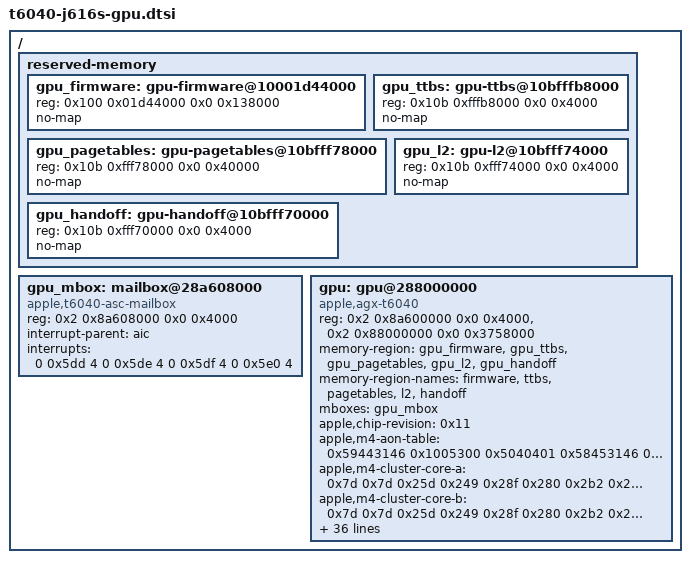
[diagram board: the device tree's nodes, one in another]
// SPDX-License-Identifier: GPL-2.0-only OR MIT
/*
 * Apple M4 Pro (T6040, j616s) GPU node and the memory iBoot reserves for the
 * GPU firmware. The node uses absolute physical addresses
 * (#address-cells = <2>, #size-cells = <2>).
 *
 * The apple,sgx-* properties are copies of the ADT /arm-io/sgx properties the
 * driver builds the firmware's hardware data and power configuration from;
 * the apple,m4-* properties hold this GPU's calibration tables (per-cluster
 * frequencies, voltages, core mask, leakage, AON table).
 */

/ {
	reserved-memory {
		#address-cells = <2>;
		#size-cells = <2>;
		ranges;

		/* __DATA segment of the GPU firmware (apple,sgx-gfx-data-*), holds its crash log */
		gpu_firmware: gpu-firmware@10001d44000 {
			reg = <0x100 0x01d44000 0x0 0x138000>;
			no-map;
		};
		/* apple,sgx-gpu-region-* */
		gpu_ttbs: gpu-ttbs@10bfffb8000 {
			reg = <0x10b 0xfffb8000 0x0 0x4000>;
			no-map;
		};
		/* apple,sgx-gfx-shared-region-* : UAT page tables */
		gpu_pagetables: gpu-pagetables@10bfff78000 {
			reg = <0x10b 0xfff78000 0x0 0x40000>;
			no-map;
		};
		/* apple,sgx-gfx-shared-l2-region-* */
		gpu_l2: gpu-l2@10bfff74000 {
			reg = <0x10b 0xfff74000 0x0 0x4000>;
			no-map;
		};
		/* apple,sgx-gfx-handoff-* */
		gpu_handoff: gpu-handoff@10bfff70000 {
			reg = <0x10b 0xfff70000 0x0 0x4000>;
			no-map;
		};
	};

	gpu_mbox: mailbox@28a608000 {
		compatible = "apple,t6040-asc-mailbox", "apple,asc-mailbox-v4";
		reg = <0x2 0x8a608000 0x0 0x4000>;
		interrupt-parent = <&aic>;
		interrupts = <0 0x5dd 4 0 0x5de 4 0 0x5df 4 0 0x5e0 4>;
		interrupt-names = "send-empty", "send-not-empty", "recv-empty", "recv-not-empty";
		#mbox-cells = <0>;
	};

	gpu: gpu@288000000 {
		compatible = "apple,agx-t6040";
		reg = <0x2 0x8a600000 0x0 0x4000>, <0x2 0x88000000 0x0 0x3758000>;
		reg-names = "asc", "sgx";
		memory-region = <&gpu_firmware>, <&gpu_ttbs>, <&gpu_pagetables>, <&gpu_l2>, <&gpu_handoff>;
		memory-region-names = "firmware", "ttbs", "pagetables", "l2", "handoff";
		mboxes = <&gpu_mbox>;

		apple,chip-revision = <0x11>;
		apple,m4-aon-table = <0x59443146 0x1005300 0x5040401 0x58453146 0x1008200 0xeff0000 0x57463146 0x1004600 0x1ff0000 0x43533146 0x1004700 0x9000800 0x4c533146 0x1005200 0x1030000 0x44543146 0x1005000 0x1010000 0x56543146 0x1005100 0x1020000 0x59443246 0x1009d00 0x5040401 0x58453246 0x100ca00 0xeff0000 0x57463246 0x1009000 0x1ff0000 0x43533246 0x1009100 0x9000800 0x4c533246 0x1009c00 0x1030000 0x44543246 0x1009a00 0x1010000 0x56543246 0x1009b00 0x1020000 0x5944314c 0x1000d00 0x5040401 0x5845314c 0x1003c00 0xaff0000 0x5746314c 0x1000000 0x1ff0000 0x4353314c 0x1000100 0x9000800 0x4c53314c 0x1000c00 0x1030000 0x4454314c 0x1000a00 0x1010000 0x5654314c 0x1000b00 0x1020000 0x31454d53 0x100da00 0x1ff0000 0x58454d53 0x100db00 0x2dff0000 0x45544d53 0x100d800 0x20a0100 0x53427462 0x1001b00 0x5090400 0x63447462 0x1001600 0x2070100 0x49467462 0x1001200 0x4050300 0x43577462 0x1001800 0x3070200 0x306d7462 0x1002000 0x1080000 0x316d7462 0x1002100 0x1080000 0x656e3064 0x1008100 0x1ff0000 0x696e3064 0x1003b00 0x1ff0000 0x526e3065 0x1003900 0x1ff0000 0x42453067 0x1006900 0x1ff0000 0x4c453067 0x1006700 0x1ff0000 0x42543067 0x1006a00 0x1ff0000 0x4c543067 0x1006800 0x1ff0000 0x52543067 0x1006b00 0x1140000 0x30653067 0x1006c00 0x2ff0000 0x31653067 0x1006e00 0x2ff0000 0x30693067 0x1007200 0x1ff0000 0x31693067 0x1007300 0x1ff0000 0x32693067 0x1007400 0x1ff0000 0x33693067 0x1007500 0x1ff0000 0x526e3067 0x1007e00 0x1ff0000 0x30743067 0x1007000 0x1ff0000 0x31743067 0x1007100 0x1ff0000 0x42453167 0x100b300 0x1ff0000 0x4c453167 0x100b100 0x1ff0000 0x42543167 0x100b400 0x1ff0000 0x4c543167 0x100b200 0x1ff0000 0x52543167 0x100b500 0x1140000 0x30653167 0x100b600 0x2ff0000 0x31653167 0x100b800 0x2ff0000 0x30693167 0x100bc00 0x1ff0000 0x31693167 0x100bd00 0x1ff0000 0x32693167 0x100be00 0x1ff0000 0x33693167 0x100bf00 0x1ff0000 0x526e3167 0x100c600 0x1ff0000 0x30743167 0x100ba00 0x1ff0000 0x31743167 0x100bb00 0x1ff0000 0x306e306c 0x1007f00 0x1ff0000 0x326e306c 0x1008000 0x1ff0000 0x306e316c 0x100c900 0x1ff0000 0x326e316c 0x1003a00 0x1ff0000 0x42453070 0x1005a00 0x1ff0000 0x4c453070 0x1005800 0x1ff0000 0x72453070 0x1007600 0x1ff0000 0x42543070 0x1005b00 0x1ff0000 0x4c543070 0x1005900 0x1ff0000 0x52543070 0x1005c00 0x1130000 0x72543070 0x1007700 0x1130000 0x30653070 0x1005d00 0x2ff0000 0x31653070 0x1005f00 0x2ff0000 0x32653070 0x1007800 0x2ff0000 0x30693070 0x1006300 0x1ff0000 0x31693070 0x1006400 0x1ff0000 0x32693070 0x1006500 0x1ff0000 0x33693070 0x1006600 0x1ff0000 0x34693070 0x1007b00 0x1ff0000 0x526e3070 0x1007c00 0x1ff0000 0x726e3070 0x1007d00 0x1ff0000 0x30743070 0x1006100 0x1ff0000 0x31743070 0x1006200 0x1ff0000 0x32743070 0x1007a00 0x1ff0000 0x42453170 0x1002400 0x1ff0000 0x4c453170 0x1002200 0x1ff0000 0x72453170 0x1003100 0x1ff0000 0x42543170 0x1002500 0x1ff0000 0x4c543170 0x1002300 0x1ff0000 0x52543170 0x1002600 0x1130000 0x72543170 0x1003200 0x1130000 0x30653170 0x1002700 0x2ff0000 0x31653170 0x1002900 0x2ff0000 0x32653170 0x1003300 0x2ff0000 0x30693170 0x1002d00 0x1ff0000 0x31693170 0x1002e00 0x1ff0000 0x32693170 0x1002f00 0x1ff0000 0x33693170 0x1003000 0x1ff0000 0x34693170 0x1003600 0x1ff0000 0x526e3170 0x1003700 0x1ff0000 0x726e3170 0x1003800 0x1ff0000 0x30743170 0x1002b00 0x1ff0000 0x31743170 0x1002c00 0x1ff0000 0x32743170 0x1003500 0x1ff0000 0x52453072 0x100c000 0x1ff0000 0x52543072 0x100c100 0x1140000 0x30653072 0x100c200 0x2ff0000 0x30693072 0x100c500 0x1ff0000 0x526e3072 0x100c800 0x1ff0000 0x30743072 0x100c400 0x1ff0000 0x42453073 0x100a400 0x1ff0000 0x4c453073 0x100a200 0x1ff0000 0x42543073 0x100a500 0x1ff0000 0x4c543073 0x100a300 0x1ff0000 0x52543073 0x100a600 0x1160000 0x30653073 0x100a700 0x2ff0000 0x31653073 0x100a900 0x2ff0000 0x30693073 0x100ad00 0x1ff0000 0x31693073 0x100ae00 0x1ff0000 0x32693073 0x100af00 0x1ff0000 0x33693073 0x100b000 0x1ff0000 0x526e3073 0x100c700 0x1ff0000 0x30743073 0x100ab00 0x1ff0000 0x31743073 0x100ac00 0x1ff0000 0x58455845 0x1000801 0xff0000 0x4554534f 0x100d003 0x20f0104 0x3254534f 0x100d203 0x20f0104 0x3354534f 0x100d403 0x20f0104 0x5845534f 0x100d603 0x2aff0004>;
		apple,m4-cluster-core-a = <0x7d 0x7d 0x25d 0x249 0x28f 0x280 0x2b2 0x2b2 0x2cb 0x2d5 0x2f3 0x302 0x31b 0x32a 0x34d 0x35c 0x384 0x393 0x3b1 0x3c0 0x406 0x415>;
		apple,m4-cluster-core-b = <0x7d 0x7d 0x25d 0x249 0x28f 0x280 0x2b2 0x2b2 0x2cb 0x2d5 0x2f3 0x302 0x31b 0x32a 0x34d 0x35c 0x384 0x393 0x3b1 0x3c0 0x406 0x415>;
		apple,m4-cluster-sram-a = <0x32a 0x32a 0x32a 0x32a 0x32a 0x32a 0x32a 0x32a 0x32a 0x32a 0x32a 0x32a 0x32a 0x32a 0x34d 0x35c 0x384 0x393 0x3b1 0x3c0 0x406 0x415>;
		apple,m4-cluster-sram-b = <0x32a 0x32a 0x32a 0x32a 0x32a 0x32a 0x32a 0x32a 0x32a 0x32a 0x32a 0x32a 0x32a 0x32a 0x34d 0x35c 0x384 0x393 0x3b1 0x3c0 0x406 0x415>;
		apple,m4-core-mask = <0xfffff>;
		apple,m4-core-voltage = <0x7d 0x25d 0x28f 0x2b2 0x2cb 0x2f3 0x31b 0x34d 0x384 0x3b1 0x406>;
		apple,m4-freq-a = <0x00 0x152 0x26a 0x31c 0x39c 0x420 0x49e 0x520 0x564 0x5be 0x62a>;
		apple,m4-freq-b = <0x00 0x152 0x26a 0x31c 0x39c 0x420 0x426 0x49e 0x4da 0x52e 0x62a>;
		apple,m4-index-a = <0x00 0x01 0x02 0x03 0x04 0x06 0x08 0x0a 0x0c 0x0e 0x0f>;
		apple,m4-index-b = <0x00 0x01 0x02 0x03 0x04 0x06 0x07 0x09 0x0b 0x0d 0x0f>;
		apple,m4-leakage = <0x44f03000 0x44f30000 0x00 0x00 0x00 0x00 0x00 0x00 0x00 0x00 0x00 0x00 0x00 0x00 0x00 0x00 0x00 0x00 0x00 0x00 0x00 0x00 0x00 0x00 0x00 0x00 0x00 0x00 0x00 0x00 0x00 0x00 0x43730000 0x43730000 0x00 0x00 0x00 0x00 0x00 0x00 0x00 0x00 0x00 0x00 0x00 0x00 0x00 0x00 0x00 0x00 0x00 0x00 0x437b0000 0x00 0x43bdc000 0x00>;
		apple,m4-max-power-mw = <0x10dfc>;
		apple,m4-memory-voltage = <0x32a 0x32a 0x32a 0x32a 0x32a 0x32a 0x32a 0x34d 0x384 0x3b1 0x406>;
		apple,m4-mtr-polynomial = <0x1000000 0x10000000 0xd38b0000 0x64ea0000 0xfbf5ff01 0x82ffff01 0x5000000 0x10000000 0x198c0000 0x73ea0000 0xfaf5ff01 0x82ffff01 0x7000000 0x10000000 0xb18f0000 0x4e90000 0x1af6ff01 0x85ffff01 0x9000000 0x10000000 0x8d8d0000 0xf0e90000 0x6f6ff01 0x83ffff01 0xb000000 0x10000000 0xe08b0000 0x77e90000 0x10f6ff01 0x84ffff01 0xd000000 0x10000000 0xc78c0000 0xf0ea0000 0xf0f5ff01 0x81ffff01 0x11000000 0x10000000 0x8f0000 0x6fea0000 0xfbf5ff01 0x82ffff01 0x15000000 0x10000000 0xb8d0000 0x30ea0000 0xf6ff01 0x83ffff01 0x19000000 0x10000000 0xe58c0000 0xcaea0000 0xf3f5ff01 0x82ffff01 0x1b000000 0x10000000 0x6a8f0000 0x3fea0000 0xfdf5ff01 0x83ffff01 0x1d000000 0x10000000 0x428f0000 0x9eb0000 0xeef5ff01 0x81ffff01>;
		apple,m4-relative-a = <0x00 0x09 0x10 0x17 0x1d 0x26 0x31 0x3c 0x45 0x4f 0x64>;
		apple,m4-relative-b = <0x00 0x00 0x16 0x24 0x2f 0x39 0x44 0x4e 0x54 0x5b 0x64>;
		apple,sgx-active-mcc-bit-vector = <0xf000000>;
		apple,sgx-afr-perf-states = <0x1000000 0x00 0x8000000 0x00 0xf8770800 0x00 0x366e01 0x00 0xf8770800 0x00 0x80782514 0x00 0xe0750900 0x00 0x80eed524 0x00 0x20120a00 0x00 0xff712f 0x00 0xf8e80a00 0x00 0xb8203b 0x00 0xe0e60b00 0x00 0x71cf46 0x00 0x70460d00 0x00 0x214152 0x00 0xb0e20d00 0x00 0x806b9e57 0x00 0x105c0c00 0x00>;
		apple,sgx-cs-perf-states = <0x1000000 0x00 0x8000000 0x00 0xf8770800 0x00 0x366e01 0x00 0xf8770800 0x00 0x80782514 0x00 0xe0750900 0x00 0x80eed524 0x00 0x20120a00 0x00 0xff712f 0x00 0xf8e80a00 0x00 0xb8203b 0x00 0xe0e60b00 0x00 0x71cf46 0x00 0x70460d00 0x00 0x214152 0x00 0xb0e20d00 0x00 0x806b9e57 0x00 0x105c0c00 0x00>;
		apple,sgx-gpu-power-sample-period = <0x8000000>;
		apple,sgx-gpu-pwr-sample-period-aic-clks = <0x400d0300>;
		apple,sgx-meta-sw-interrupt = <0x84404102 0x5000000 0x84424102 0x5000000 0x80000000>;
	};
};
